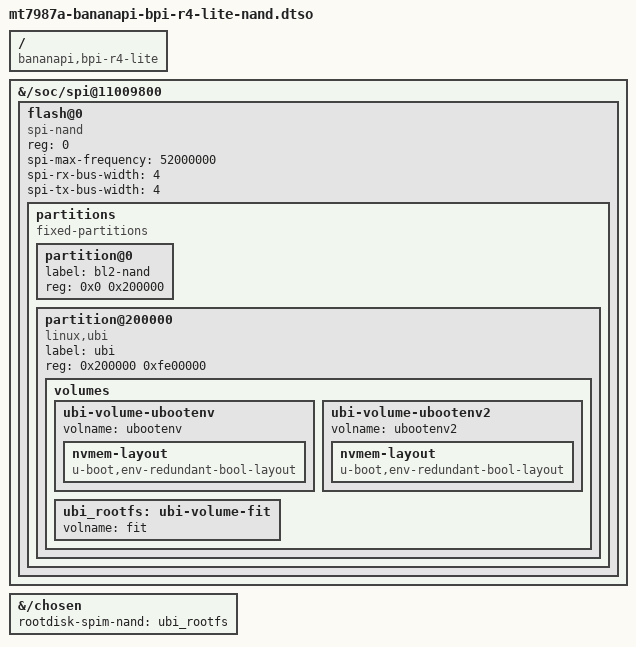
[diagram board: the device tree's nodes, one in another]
/dts-v1/;
/plugin/;

/ {
	compatible = "bananapi,bpi-r4-lite",
		     "mediatek,mt7987a", "mediatek,mt7987";
};

&{/soc/spi@11009800} {
	#address-cells = <1>;
	#size-cells = <0>;

	flash@0 {
		compatible = "spi-nand";
		reg = <0>;
		spi-max-frequency = <52000000>;
		spi-rx-bus-width = <4>;
		spi-tx-bus-width = <4>;

		partitions {
			compatible = "fixed-partitions";
			#address-cells = <1>;
			#size-cells = <1>;

			partition@0 {
				label = "bl2-nand";
				reg = <0x0 0x200000>;
			};

			partition@200000 {
				label = "ubi";
				reg = <0x200000 0xfe00000>;
				compatible = "linux,ubi";

				volumes {
					ubi-volume-ubootenv {
						volname = "ubootenv";
						nvmem-layout {
							compatible = "u-boot,env-redundant-bool-layout";
						};
					};

					ubi-volume-ubootenv2 {
						volname = "ubootenv2";
						nvmem-layout {
							compatible = "u-boot,env-redundant-bool-layout";
						};
					};

					ubi_rootfs: ubi-volume-fit {
						volname = "fit";
					};
				};
			};
		};
	};
};

&{/chosen} {
	rootdisk-spim-nand = <&ubi_rootfs>;
};
